AUTOSAR XML (schema 4-3-0)
package /Dimmer
  application-sw-component-type:
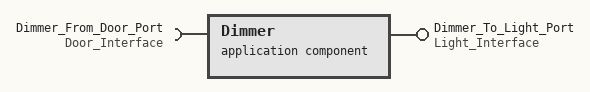
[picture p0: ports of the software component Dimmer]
    application sw component type Dimmer
      require port Dimmer_From_Door_Port: nonqueued-receiver-com-spec=Array_Data_Element, required-interface=Door_Interface
      provide port Dimmer_To_Light_Port: nonqueued-sender-com-spec=Struct_Data_Element, provided-interface=Light_Interface
      behavior Dimmer_InternalBehavior
    swc implementation Dimmer_Implementation: behavior=Dimmer_InternalBehavior
